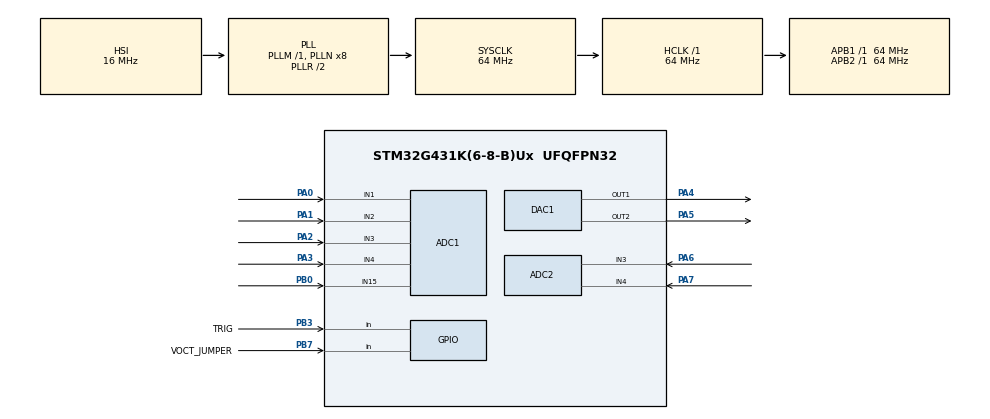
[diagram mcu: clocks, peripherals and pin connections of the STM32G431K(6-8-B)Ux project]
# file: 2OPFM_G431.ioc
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ADC1.Channel-0\#ChannelRegularConversion=ADC_CHANNEL_1
ADC1.Channel-1\#ChannelRegularConversion=ADC_CHANNEL_2
ADC1.Channel-2\#ChannelRegularConversion=ADC_CHANNEL_3
ADC1.Channel-3\#ChannelRegularConversion=ADC_CHANNEL_4
ADC1.Channel-4\#ChannelRegularConversion=ADC_CHANNEL_15
ADC1.Channel-5\#ChannelRegularConversion=ADC_CHANNEL_VREFINT
ADC1.DMAContinuousRequests=ENABLE
ADC1.EOCSelection=ADC_EOC_SEQ_CONV
ADC1.ExternalTrigConv=ADC_EXTERNALTRIG_T3_TRGO
ADC1.NbrOfConversion=6
ADC1.NbrOfConversionFlag=1
ADC1.OffsetNumber-0\#ChannelRegularConversion=ADC_OFFSET_NONE
ADC1.OffsetNumber-1\#ChannelRegularConversion=ADC_OFFSET_NONE
ADC1.OffsetNumber-2\#ChannelRegularConversion=ADC_OFFSET_NONE
ADC1.OffsetNumber-3\#ChannelRegularConversion=ADC_OFFSET_NONE
ADC1.OffsetNumber-4\#ChannelRegularConversion=ADC_OFFSET_NONE
ADC1.OffsetNumber-5\#ChannelRegularConversion=ADC_OFFSET_NONE
ADC1.Rank-0\#ChannelRegularConversion=1
ADC1.Rank-1\#ChannelRegularConversion=2
ADC1.Rank-2\#ChannelRegularConversion=3
ADC1.Rank-3\#ChannelRegularConversion=4
ADC1.Rank-4\#ChannelRegularConversion=5
ADC1.Rank-5\#ChannelRegularConversion=6
ADC1.SamplingTime-0\#ChannelRegularConversion=ADC_SAMPLETIME_247CYCLES_5
ADC1.SamplingTime-1\#ChannelRegularConversion=ADC_SAMPLETIME_247CYCLES_5
ADC1.SamplingTime-2\#ChannelRegularConversion=ADC_SAMPLETIME_92CYCLES_5
ADC1.SamplingTime-3\#ChannelRegularConversion=ADC_SAMPLETIME_247CYCLES_5
ADC1.SamplingTime-4\#ChannelRegularConversion=ADC_SAMPLETIME_247CYCLES_5
ADC1.SamplingTime-5\#ChannelRegularConversion=ADC_SAMPLETIME_247CYCLES_5
ADC1.master=1
ADC2.Channel-0\#ChannelRegularConversion=ADC_CHANNEL_3
ADC2.Channel-1\#ChannelRegularConversion=ADC_CHANNEL_4
ADC2.DMAContinuousRequests=ENABLE
ADC2.EOCSelection=ADC_EOC_SEQ_CONV
ADC2.ExternalTrigConv=ADC_EXTERNALTRIG_T2_TRGO
ADC2.NbrOfConversion=2
ADC2.NbrOfConversionFlag=1
ADC2.OffsetNumber-0\#ChannelRegularConversion=ADC_OFFSET_NONE
ADC2.OffsetNumber-1\#ChannelRegularConversion=ADC_OFFSET_NONE
ADC2.Rank-0\#ChannelRegularConversion=1
ADC2.Rank-1\#ChannelRegularConversion=2
ADC2.SamplingTime-0\#ChannelRegularConversion=ADC_SAMPLETIME_24CYCLES_5
ADC2.SamplingTime-1\#ChannelRegularConversion=ADC_SAMPLETIME_24CYCLES_5
DAC1.DAC_Channel-DAC_OUT2=DAC_CHANNEL_2
DAC1.DAC_SignedFormat-DAC_OUT1=DISABLE
DAC1.DAC_SignedFormat-DAC_OUT2=DISABLE
Dma.ADC1.1.Direction=DMA_PERIPH_TO_MEMORY
Dma.ADC1.1.EventEnable=DISABLE
Dma.ADC1.1.Instance=DMA1_Channel2
Dma.ADC1.1.MemDataAlignment=DMA_MDATAALIGN_HALFWORD
Dma.ADC1.1.MemInc=DMA_MINC_ENABLE
Dma.ADC1.1.Mode=DMA_CIRCULAR
Dma.ADC1.1.PeriphDataAlignment=DMA_PDATAALIGN_HALFWORD
Dma.ADC1.1.PeriphInc=DMA_PINC_DISABLE
Dma.ADC1.1.Polarity=HAL_DMAMUX_REQ_GEN_RISING
Dma.ADC1.1.Priority=DMA_PRIORITY_MEDIUM
Dma.ADC1.1.RequestNumber=1
Dma.ADC1.1.SignalID=NONE
Dma.ADC1.1.SyncEnable=DISABLE
Dma.ADC1.1.SyncPolarity=HAL_DMAMUX_SYNC_NO_EVENT
Dma.ADC1.1.SyncRequestNumber=1
Dma.ADC1.1.SyncSignalID=NONE
Dma.ADC2.0.Direction=DMA_PERIPH_TO_MEMORY
Dma.ADC2.0.EventEnable=DISABLE
Dma.ADC2.0.Instance=DMA1_Channel1
Dma.ADC2.0.MemDataAlignment=DMA_MDATAALIGN_HALFWORD
Dma.ADC2.0.MemInc=DMA_MINC_ENABLE
Dma.ADC2.0.Mode=DMA_CIRCULAR
Dma.ADC2.0.PeriphDataAlignment=DMA_PDATAALIGN_HALFWORD
Dma.ADC2.0.PeriphInc=DMA_PINC_DISABLE
Dma.ADC2.0.Polarity=HAL_DMAMUX_REQ_GEN_RISING
Dma.ADC2.0.Priority=DMA_PRIORITY_VERY_HIGH
Dma.ADC2.0.RequestNumber=1
Dma.ADC2.0.SignalID=NONE
Dma.ADC2.0.SyncEnable=DISABLE
Dma.ADC2.0.SyncPolarity=HAL_DMAMUX_SYNC_NO_EVENT
Dma.ADC2.0.SyncRequestNumber=1
Dma.ADC2.0.SyncSignalID=NONE
Dma.Request0=ADC2
Dma.Request1=ADC1
Mcu.Family=STM32G4
Mcu.Name=STM32G431K(6-8-B)Ux
Mcu.Package=UFQFPN32
NVIC.PriorityGroup=NVIC_PRIORITYGROUP_4
NVIC.TIM2_IRQn=true\:0\:0\:false\:false\:true\:true\:true
NVIC.TIM3_IRQn=true\:1\:0\:true\:false\:true\:true\:true
PA0.Mode=IN1-Single-Ended
PA0.Signal=ADC1_IN1
PA1.Mode=IN2-Single-Ended
PA1.Signal=ADC1_IN2
PA2.Mode=IN3-Single-Ended
PA2.Signal=ADC1_IN3
PA3.Mode=IN4-Single-Ended
PA3.Signal=ADC1_IN4
PA4.Signal=COMP_DAC11_group
PA5.Signal=COMP_DAC12_group
PA6.Mode=IN3-Single-Ended
PA6.Signal=ADC2_IN3
PA7.Mode=IN4-Single-Ended
PA7.Signal=ADC2_IN4
PB0.Mode=IN15-Single-Ended
PB0.Signal=ADC1_IN15
PB3.GPIO_Label=TRIG
PB3.GPIO_PuPd=GPIO_PULLUP
PB3.Signal=GPIO_Input
PB7.GPIO_Label=VOCT_JUMPER
PB7.GPIO_PuPd=GPIO_PULLUP
PB7.Signal=GPIO_Input
ProjectManager.HeapSize=0x0
ProjectManager.StackSize=0x400
ProjectManager.TargetToolchain=STM32CubeIDE
RCC.ADC12Freq_Value=64000000
RCC.AHBFreq_Value=64000000
RCC.APB1Freq_Value=64000000
RCC.APB1TimFreq_Value=64000000
RCC.APB2Freq_Value=64000000
RCC.APB2TimFreq_Value=64000000
RCC.CortexFreq_Value=64000000
RCC.EXTERNAL_CLOCK_VALUE=12288000
RCC.HCLKFreq_Value=64000000
RCC.HSE_VALUE=8000000
RCC.HSI48_VALUE=48000000
RCC.HSI_VALUE=16000000
RCC.LSE_VALUE=32768
RCC.SYSCLKFreq_VALUE=64000000
RCC.SYSCLKSource=RCC_SYSCLKSOURCE_PLLCLK
RCC.USBFreq_Value=64000000
RCC.VCOOutputFreq_Value=128000000
SH.COMP_DAC11_group.0=DAC1_OUT1,DAC_OUT1
SH.COMP_DAC12_group.0=DAC1_OUT2,DAC_OUT2
TIM2.PeriodNoDither=1600
TIM2.TIM_MasterOutputTrigger=TIM_TRGO_UPDATE
TIM3.PeriodNoDither=12800
TIM3.TIM_MasterOutputTrigger=TIM_TRGO_UPDATE
VP_ADC1_Vref_Input.Mode=IN-Vrefint
VP_SYS_VS_DBSignals.Mode=DisableDeadBatterySignals
VP_TIM2_VS_ClockSourceINT.Mode=Internal
VP_TIM3_VS_ClockSourceINT.Mode=Internal
board=custom

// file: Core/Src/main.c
/* USER CODE BEGIN Header */
/**
 ******************************************************************************
 * @file           : main.c
 * @brief          : Main program body
 ******************************************************************************
 * @attention
 *
 * Copyright (c) 2024 STMicroelectronics.
 * All rights reserved.
 *
 * This software is licensed under terms that can be found in the LICENSE file
 * in the root directory of this software component.
 * If no LICENSE file comes with this software, it is provided AS-IS.
 *
 ******************************************************************************
 */
/* USER CODE END Header */
#include "main.h"
#include "adc.h"
#include "dac.h"
#include "dma.h"
#include "tim.h"
#include "gpio.h"

/* USER CODE BEGIN PV */
volatile float khz_in_scaling = 0.25f;

/* USER CODE END PV */

void SystemClock_Config(void);

int main(void)
{

  /* MCU Configuration--------------------------------------------------------*/

  /* Reset of all peripherals, Initializes the Flash interface and the Systick. */
  HAL_Init();

  /* Configure the system clock */
  SystemClock_Config();

  /* Initialize all configured peripherals */
  MX_GPIO_Init();
  MX_DMA_Init();
  MX_ADC1_Init();
  MX_ADC2_Init();
  MX_DAC1_Init();
  MX_TIM2_Init();
  MX_TIM3_Init();
  /* USER CODE BEGIN 2 */

	ADC_Start();
	TIM_Start();
	DAC_Start();

	dynamic_smooth_init(&dynamic_smooth_a, 0.05f, 0.5f);
	adsr_structinit(&OP1.ADSR);

	VREFINT_CAL = *VREFINT_CAL_ADDR;

	while (adc1_data[VREFINT_PIN] == 0) {
		//wait for values!
	}

	for(int i=0; i<100000; i++) {
		vdd_mv += ((3000.0f * VREFINT_CAL / (float)(adc1_data[VREFINT_PIN])) - vdd_mv) * 0.2f;
	}

	khz_correction = 3300.0f / vdd_mv;
	khz_in_mv = adc2_data[KHZ_JACK] * 3300 >> 12;

  /* USER CODE END 2 */

  /* Infinite loop */
  /* USER CODE BEGIN WHILE */
	while (1) {
		loop();
    /* USER CODE END WHILE */

	}
}

void SystemClock_Config(void)
{
  RCC_OscInitTypeDef RCC_OscInitStruct = {0};
  RCC_ClkInitTypeDef RCC_ClkInitStruct = {0};

  /** Configure the main internal regulator output voltage
  */
  HAL_PWREx_ControlVoltageScaling(PWR_REGULATOR_VOLTAGE_SCALE1);
  /** Initializes the RCC Oscillators according to the specified parameters
  * in the RCC_OscInitTypeDef structure.
  */
  RCC_OscInitStruct.OscillatorType = RCC_OSCILLATORTYPE_HSI;
  RCC_OscInitStruct.HSIState = RCC_HSI_ON;
  RCC_OscInitStruct.HSICalibrationValue = RCC_HSICALIBRATION_DEFAULT;
  RCC_OscInitStruct.PLL.PLLState = RCC_PLL_ON;
  RCC_OscInitStruct.PLL.PLLSource = RCC_PLLSOURCE_HSI;
  RCC_OscInitStruct.PLL.PLLM = RCC_PLLM_DIV1;
  RCC_OscInitStruct.PLL.PLLN = 8;
  RCC_OscInitStruct.PLL.PLLP = RCC_PLLP_DIV2;
  RCC_OscInitStruct.PLL.PLLQ = RCC_PLLQ_DIV2;
  RCC_OscInitStruct.PLL.PLLR = RCC_PLLR_DIV2;
  if (HAL_RCC_OscConfig(&RCC_OscInitStruct) != HAL_OK)
  {
    Error_Handler();
  }
  /** Initializes the CPU, AHB and APB buses clocks
  */
  RCC_ClkInitStruct.ClockType = RCC_CLOCKTYPE_HCLK|RCC_CLOCKTYPE_SYSCLK
                              |RCC_CLOCKTYPE_PCLK1|RCC_CLOCKTYPE_PCLK2;
  RCC_ClkInitStruct.SYSCLKSource = RCC_SYSCLKSOURCE_PLLCLK;
  RCC_ClkInitStruct.AHBCLKDivider = RCC_SYSCLK_DIV1;
  RCC_ClkInitStruct.APB1CLKDivider = RCC_HCLK_DIV1;
  RCC_ClkInitStruct.APB2CLKDivider = RCC_HCLK_DIV1;

  if (HAL_RCC_ClockConfig(&RCC_ClkInitStruct, FLASH_LATENCY_1) != HAL_OK)
  {
    Error_Handler();
  }
}

void Error_Handler(void)
{
	__disable_irq();
	while (1) {
	}
}
